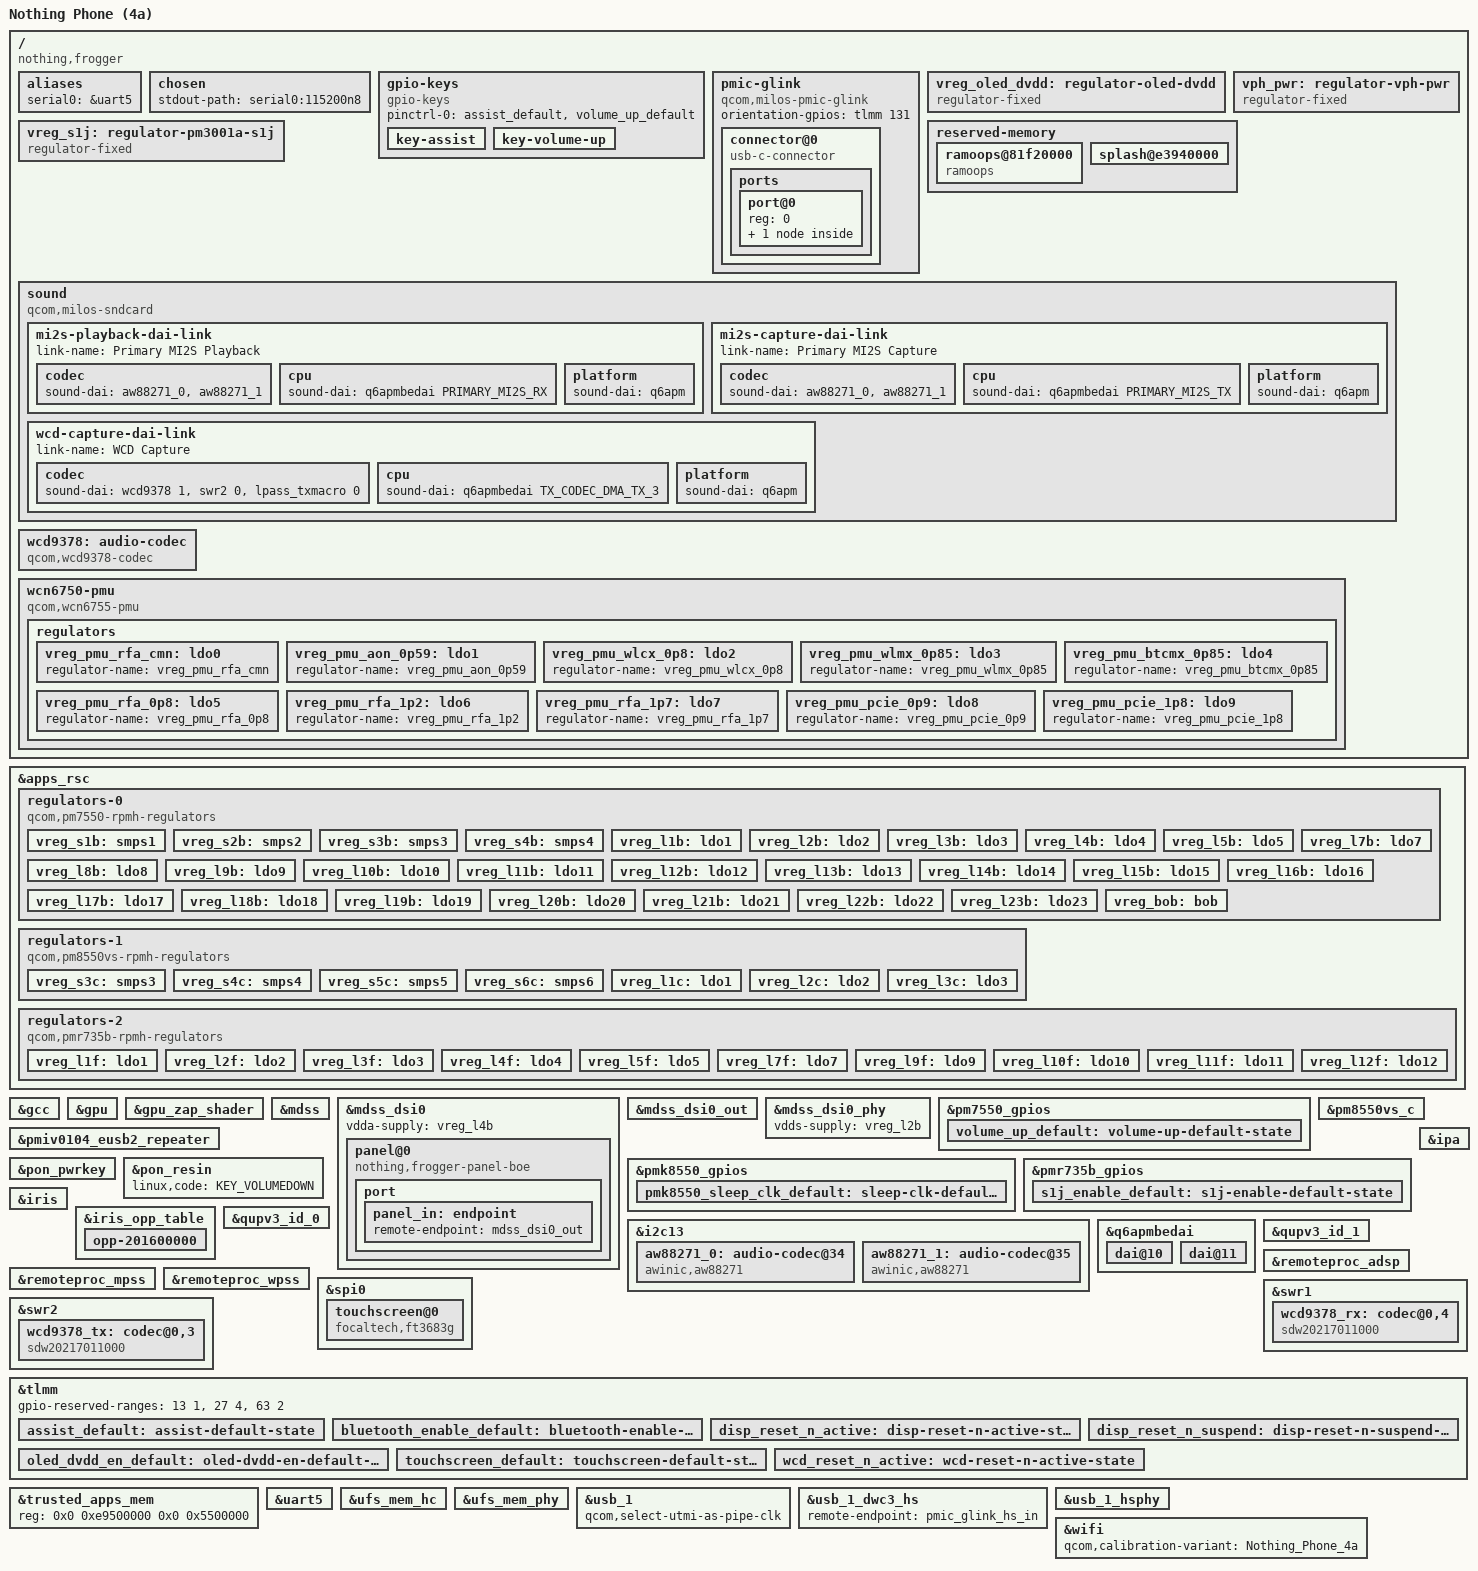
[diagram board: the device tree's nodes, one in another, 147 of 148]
// SPDX-License-Identifier: BSD-3-Clause

/dts-v1/;

#define PMIV0104_SID 7

#include <dt-bindings/pinctrl/qcom,pmic-gpio.h>
#include <dt-bindings/regulator/qcom,rpmh-regulator.h>

#include "milos.dtsi"
#include "pm7550.dtsi"
#include "pm8550vs.dtsi"
#include "pmiv0104.dtsi" /* PMIV0102 */
#include "pmk8550.dtsi" /* PMK7635 */
#include "pmr735b.dtsi"

/ {
	model = "Nothing Phone (4a)";
	compatible = "nothing,frogger", "qcom,milos";
	chassis-type = "handset";

	aliases {
		serial0 = &uart5;
	};

	chosen {
		stdout-path = "serial0:115200n8";
	};

	gpio-keys {
		compatible = "gpio-keys";

		pinctrl-0 = <&assist_default>, <&volume_up_default>;
		pinctrl-names = "default";

		key-assist {
			gpios = <&tlmm 71 GPIO_ACTIVE_LOW>;
			label = "Assistant";
			linux,code = <KEY_LEFTMETA>;
		};

		key-volume-up {
			gpios = <&pm7550_gpios 6 GPIO_ACTIVE_LOW>;
			label = "Volume Up";
			linux,code = <KEY_VOLUMEUP>;
		};
	};

	pmic-glink {
		compatible = "qcom,milos-pmic-glink",
			     "qcom,sm8550-pmic-glink",
			     "qcom,pmic-glink";
		#address-cells = <1>;
		#size-cells = <0>;
		orientation-gpios = <&tlmm 131 GPIO_ACTIVE_HIGH>;

		connector@0 {
			compatible = "usb-c-connector";
			reg = <0>;

			power-role = "dual";
			data-role = "dual";

			ports {
				#address-cells = <1>;
				#size-cells = <0>;

				port@0 {
					reg = <0>;

					pmic_glink_hs_in: endpoint {
						remote-endpoint = <&usb_1_dwc3_hs>;
					};
				};
			};
		};
	};

	vreg_oled_dvdd: regulator-oled-dvdd {
		compatible = "regulator-fixed";
		regulator-name = "oled_dvdd";
		regulator-min-microvolt = <1800000>;
		regulator-max-microvolt = <1800000>;

		gpio = <&tlmm 109 GPIO_ACTIVE_HIGH>;
		enable-active-high;

		pinctrl-0 = <&oled_dvdd_en_default>;
		pinctrl-names = "default";

		/* Left on by the bootloader */
		regulator-boot-on;
	};

	vreg_s1j: regulator-pm3001a-s1j {
		compatible = "regulator-fixed";
		regulator-name = "pm3001a_s1j";
		regulator-min-microvolt = <2200000>;
		regulator-max-microvolt = <2200000>;
		startup-delay-us = <1000>;

		/*
		 * WCN6750 iPA supply. Only the wcn6750-pmu consumes it, and
		 * nothing powers that sequencer up without Bluetooth, so keep
		 * it on for Wi-Fi (downstream enables it with the WLAN).
		 */
		regulator-always-on;

		gpio = <&pmr735b_gpios 1 GPIO_ACTIVE_HIGH>;
		enable-active-high;

		vin-supply = <&vph_pwr>;

		pinctrl-0 = <&s1j_enable_default>;
		pinctrl-names = "default";
	};

	vph_pwr: regulator-vph-pwr {
		compatible = "regulator-fixed";
		regulator-name = "vph_pwr";
		regulator-min-microvolt = <3700000>;
		regulator-max-microvolt = <3700000>;

		regulator-always-on;
		regulator-boot-on;
	};

	reserved-memory {
		#address-cells = <2>;
		#size-cells = <2>;
		ranges;

		ramoops@81f20000 {
			compatible = "ramoops";
			reg = <0x0 0x81f20000 0x0 0x400000>;
			console-size = <0x200000>;
			mem-type = <2>;
			pmsg-size = <0x200000>;
		};

		/*
		 * Bootloader splash buffer. ABL leaves the display running only
		 * when this node is named exactly "splash_region"; under any
		 * other name it powers display and controller down before
		 * booting Linux. Handing over a live splash breaks the MDSS
		 * memory path on this phone, so let ABL turn it off.
		 */
		splash@e3940000 {
			reg = <0x0 0xe3940000 0x0 0x2b00000>;
			no-map;
		};
	};

	sound {
		compatible = "qcom,milos-sndcard", "qcom,sm8450-sndcard";
		model = "Nothing Phone (4a)";
		audio-routing = "AMIC1", "MIC BIAS1",
				"AMIC2", "MIC BIAS2",
				"AMIC3", "MIC BIAS3",
				"TX SWR_INPUT0", "ADC1_OUTPUT",
				"TX SWR_INPUT4", "ADC2_OUTPUT",
				"TX SWR_INPUT8", "ADC3_OUTPUT";

		pinctrl-0 = <&i2s0_active>;
		pinctrl-1 = <&i2s0_sleep>;
		pinctrl-names = "default",
				"sleep";

		mi2s-playback-dai-link {
			link-name = "Primary MI2S Playback";

			codec {
				sound-dai = <&aw88271_0>, <&aw88271_1>;
			};

			cpu {
				sound-dai = <&q6apmbedai PRIMARY_MI2S_RX>;
			};

			platform {
				sound-dai = <&q6apm>;
			};
		};

		/* The amplifiers' V/I feedback, for DSP speaker protection */
		mi2s-capture-dai-link {
			link-name = "Primary MI2S Capture";

			codec {
				sound-dai = <&aw88271_0>, <&aw88271_1>;
			};

			cpu {
				sound-dai = <&q6apmbedai PRIMARY_MI2S_TX>;
			};

			platform {
				sound-dai = <&q6apm>;
			};
		};

		/* Keep this after the MI2S links: the V/I holder uses PCMs 0 and 1 */
		wcd-capture-dai-link {
			link-name = "WCD Capture";

			codec {
				sound-dai = <&wcd9378 1>, <&swr2 0>, <&lpass_txmacro 0>;
			};

			cpu {
				sound-dai = <&q6apmbedai TX_CODEC_DMA_TX_3>;
			};

			platform {
				sound-dai = <&q6apm>;
			};
		};
	};

	wcd9378: audio-codec {
		compatible = "qcom,wcd9378-codec";

		pinctrl-0 = <&wcd_reset_n_active>;
		pinctrl-names = "default";

		reset-gpios = <&tlmm 162 GPIO_ACTIVE_LOW>;

		vdd-buck-supply = <&vreg_l8b>;
		vdd-rxtx-supply = <&vreg_l7b>;
		vdd-io-supply = <&vreg_l7b>;
		vdd-mic-bias-supply = <&vreg_bob>;

		qcom,micbias1-microvolt = <2750000>;
		qcom,micbias2-microvolt = <2700000>;
		qcom,micbias3-microvolt = <2750000>;

		qcom,rx-device = <&wcd9378_rx>;
		qcom,tx-device = <&wcd9378_tx>;

		#sound-dai-cells = <1>;
	};

	wcn6750-pmu {
		compatible = "qcom,wcn6755-pmu", "qcom,wcn6750-pmu";

		vddaon-supply = <&vreg_s3b>;
		vddasd-supply = <&vreg_l7b>;
		vddpmu-supply = <&vreg_s3b>;
		vddrfa0p8-supply = <&vreg_s3b>;
		vddrfa1p2-supply = <&vreg_s2b>;
		vddrfa1p7-supply = <&vreg_s1b>;
		vddrfa2p2-supply = <&vreg_s1j>;

		bt-enable-gpios = <&tlmm 53 GPIO_ACTIVE_HIGH>;

		clocks = <&rpmhcc RPMH_RF_CLK1>;

		pinctrl-0 = <&bluetooth_enable_default>, <&pmk8550_sleep_clk_default>;
		pinctrl-names = "default";

		regulators {
			vreg_pmu_rfa_cmn: ldo0 {
				regulator-name = "vreg_pmu_rfa_cmn";
			};

			vreg_pmu_aon_0p59: ldo1 {
				regulator-name = "vreg_pmu_aon_0p59";
			};

			vreg_pmu_wlcx_0p8: ldo2 {
				regulator-name = "vreg_pmu_wlcx_0p8";
			};

			vreg_pmu_wlmx_0p85: ldo3 {
				regulator-name = "vreg_pmu_wlmx_0p85";
			};

			vreg_pmu_btcmx_0p85: ldo4 {
				regulator-name = "vreg_pmu_btcmx_0p85";
			};

			vreg_pmu_rfa_0p8: ldo5 {
				regulator-name = "vreg_pmu_rfa_0p8";
			};

			vreg_pmu_rfa_1p2: ldo6 {
				regulator-name = "vreg_pmu_rfa_1p2";
			};

			vreg_pmu_rfa_1p7: ldo7 {
				regulator-name = "vreg_pmu_rfa_1p7";
			};

			vreg_pmu_pcie_0p9: ldo8 {
				regulator-name = "vreg_pmu_pcie_0p9";
			};

			vreg_pmu_pcie_1p8: ldo9 {
				regulator-name = "vreg_pmu_pcie_1p8";
			};
		};
	};
};

&apps_rsc {
	regulators-0 {
		compatible = "qcom,pm7550-rpmh-regulators";

		vdd-l1-supply = <&vreg_s1b>;
		vdd-l2-l3-supply = <&vreg_s3b>;
		vdd-l4-l5-supply = <&vreg_s2b>;
		vdd-l7-supply = <&vreg_s1b>;
		vdd-l8-supply = <&vreg_s1b>;
		vdd-l9-l10-supply = <&vreg_s1b>;
		vdd-l11-supply = <&vreg_s1b>;
		vdd-l12-l14-supply = <&vreg_bob>;
		vdd-l13-l16-supply = <&vreg_bob>;
		vdd-l15-l17-l18-l19-l20-l21-l22-l23-supply = <&vreg_bob>;
		vdd-s1-supply = <&vph_pwr>;
		vdd-s2-supply = <&vph_pwr>;
		vdd-s3-supply = <&vph_pwr>;
		vdd-s4-supply = <&vph_pwr>;
		vdd-s5-supply = <&vph_pwr>;
		vdd-s6-supply = <&vph_pwr>;
		vdd-bob-supply = <&vph_pwr>;

		qcom,pmic-id = "b";

		vreg_s1b: smps1 {
			regulator-name = "vreg_s1b";
			regulator-min-microvolt = <1800000>;
			regulator-max-microvolt = <2080000>;
			regulator-initial-mode = <RPMH_REGULATOR_MODE_HPM>;
		};

		vreg_s2b: smps2 {
			regulator-name = "vreg_s2b";
			regulator-min-microvolt = <1256000>;
			regulator-max-microvolt = <1408000>;
			regulator-initial-mode = <RPMH_REGULATOR_MODE_HPM>;
		};

		vreg_s3b: smps3 {
			regulator-name = "vreg_s3b";
			regulator-min-microvolt = <880000>;
			regulator-max-microvolt = <1040000>;
			regulator-initial-mode = <RPMH_REGULATOR_MODE_HPM>;
		};

		vreg_s4b: smps4 {
			regulator-name = "vreg_s4b";
			regulator-min-microvolt = <300000>;
			regulator-max-microvolt = <1004000>;
			regulator-initial-mode = <RPMH_REGULATOR_MODE_HPM>;
		};

		vreg_l1b: ldo1 {
			regulator-name = "vreg_l1b";
			regulator-min-microvolt = <1800000>;
			regulator-max-microvolt = <1800000>;
			regulator-initial-mode = <RPMH_REGULATOR_MODE_HPM>;
		};

		vreg_l2b: ldo2 {
			regulator-name = "vreg_l2b";
			regulator-min-microvolt = <880000>;
			regulator-max-microvolt = <912000>;
			regulator-initial-mode = <RPMH_REGULATOR_MODE_HPM>;
		};

		vreg_l3b: ldo3 {
			regulator-name = "vreg_l3b";
			regulator-min-microvolt = <880000>;
			regulator-max-microvolt = <912000>;
			regulator-initial-mode = <RPMH_REGULATOR_MODE_HPM>;
		};

		vreg_l4b: ldo4 {
			regulator-name = "vreg_l4b";
			regulator-min-microvolt = <1200000>;
			regulator-max-microvolt = <1200000>;
			regulator-initial-mode = <RPMH_REGULATOR_MODE_HPM>;
		};

		vreg_l5b: ldo5 {
			regulator-name = "vreg_l5b";
			regulator-min-microvolt = <1200000>;
			regulator-max-microvolt = <1200000>;
			regulator-initial-mode = <RPMH_REGULATOR_MODE_HPM>;
		};

		vreg_l7b: ldo7 {
			regulator-name = "vreg_l7b";
			regulator-min-microvolt = <1800000>;
			regulator-max-microvolt = <1800000>;
			regulator-initial-mode = <RPMH_REGULATOR_MODE_HPM>;
		};

		vreg_l8b: ldo8 {
			regulator-name = "vreg_l8b";
			regulator-min-microvolt = <1800000>;
			regulator-max-microvolt = <1800000>;
			regulator-initial-mode = <RPMH_REGULATOR_MODE_HPM>;
		};

		vreg_l9b: ldo9 {
			regulator-name = "vreg_l9b";
			regulator-min-microvolt = <1800000>;
			regulator-max-microvolt = <1800000>;
			regulator-initial-mode = <RPMH_REGULATOR_MODE_HPM>;
		};

		vreg_l10b: ldo10 {
			regulator-name = "vreg_l10b";
			regulator-min-microvolt = <1800000>;
			regulator-max-microvolt = <1800000>;
			regulator-initial-mode = <RPMH_REGULATOR_MODE_HPM>;
		};

		vreg_l11b: ldo11 {
			regulator-name = "vreg_l11b";
			regulator-min-microvolt = <1800000>;
			regulator-max-microvolt = <1800000>;
			regulator-initial-mode = <RPMH_REGULATOR_MODE_HPM>;
		};

		vreg_l12b: ldo12 {
			regulator-name = "vreg_l12b";
			/*
			 * Skip voltage voting for UFS VCC.
			 */
			regulator-initial-mode = <RPMH_REGULATOR_MODE_HPM>;
		};

		vreg_l13b: ldo13 {
			regulator-name = "vreg_l13b";
			regulator-min-microvolt = <2700000>;
			regulator-max-microvolt = <3300000>;
			regulator-initial-mode = <RPMH_REGULATOR_MODE_HPM>;
		};

		vreg_l14b: ldo14 {
			regulator-name = "vreg_l14b";
			regulator-min-microvolt = <3300000>;
			regulator-max-microvolt = <3304000>;
			regulator-initial-mode = <RPMH_REGULATOR_MODE_HPM>;
		};

		vreg_l15b: ldo15 {
			regulator-name = "vreg_l15b";
			regulator-min-microvolt = <3300000>;
			regulator-max-microvolt = <3304000>;
			regulator-initial-mode = <RPMH_REGULATOR_MODE_HPM>;
		};

		vreg_l16b: ldo16 {
			regulator-name = "vreg_l16b";
			regulator-min-microvolt = <3304000>;
			regulator-max-microvolt = <3304000>;
			regulator-initial-mode = <RPMH_REGULATOR_MODE_HPM>;
		};

		vreg_l17b: ldo17 {
			regulator-name = "vreg_l17b";
			regulator-min-microvolt = <3104000>;
			regulator-max-microvolt = <3104000>;
			regulator-initial-mode = <RPMH_REGULATOR_MODE_HPM>;
		};

		vreg_l18b: ldo18 {
			regulator-name = "vreg_l18b";
			regulator-min-microvolt = <2800000>;
			regulator-max-microvolt = <2800000>;
			regulator-initial-mode = <RPMH_REGULATOR_MODE_HPM>;
		};

		vreg_l19b: ldo19 {
			regulator-name = "vreg_l19b";
			regulator-min-microvolt = <3000000>;
			regulator-max-microvolt = <3000000>;
			regulator-initial-mode = <RPMH_REGULATOR_MODE_HPM>;
		};

		vreg_l20b: ldo20 {
			regulator-name = "vreg_l20b";
			regulator-min-microvolt = <1620000>;
			regulator-max-microvolt = <3544000>;
			regulator-initial-mode = <RPMH_REGULATOR_MODE_HPM>;
		};

		vreg_l21b: ldo21 {
			regulator-name = "vreg_l21b";
			regulator-min-microvolt = <1620000>;
			regulator-max-microvolt = <3544000>;
			regulator-initial-mode = <RPMH_REGULATOR_MODE_HPM>;
		};

		vreg_l22b: ldo22 {
			regulator-name = "vreg_l22b";
			regulator-min-microvolt = <3296000>;
			regulator-max-microvolt = <3296000>;
			regulator-initial-mode = <RPMH_REGULATOR_MODE_HPM>;
		};

		vreg_l23b: ldo23 {
			regulator-name = "vreg_l23b";
			regulator-min-microvolt = <1650000>;
			regulator-max-microvolt = <3544000>;
			regulator-initial-mode = <RPMH_REGULATOR_MODE_HPM>;
		};

		vreg_bob: bob {
			regulator-name = "vreg_bob";
			regulator-min-microvolt = <3008000>;
			regulator-max-microvolt = <3960000>;
			regulator-initial-mode = <RPMH_REGULATOR_MODE_HPM>;
		};
	};

	regulators-1 {
		compatible = "qcom,pm8550vs-rpmh-regulators";

		vdd-l1-supply = <&vreg_s3b>;
		vdd-l2-supply = <&vreg_s3b>;
		vdd-l3-supply = <&vreg_s3b>;
		vdd-s3-supply = <&vph_pwr>;
		vdd-s4-supply = <&vph_pwr>;
		vdd-s5-supply = <&vph_pwr>;
		vdd-s6-supply = <&vph_pwr>;

		qcom,pmic-id = "c";

		vreg_s3c: smps3 {
			regulator-name = "vreg_s3c";
			regulator-min-microvolt = <1010000>;
			regulator-max-microvolt = <1120000>;
			regulator-initial-mode = <RPMH_REGULATOR_MODE_HPM>;
		};

		vreg_s4c: smps4 {
			regulator-name = "vreg_s4c";
			regulator-min-microvolt = <352000>;
			regulator-max-microvolt = <812000>;
			regulator-initial-mode = <RPMH_REGULATOR_MODE_HPM>;
		};

		vreg_s5c: smps5 {
			regulator-name = "vreg_s5c";
			regulator-min-microvolt = <540000>;
			regulator-max-microvolt = <884000>;
			regulator-initial-mode = <RPMH_REGULATOR_MODE_HPM>;
		};

		vreg_s6c: smps6 {
			regulator-name = "vreg_s6c";
			regulator-min-microvolt = <352000>;
			regulator-max-microvolt = <904000>;
			regulator-initial-mode = <RPMH_REGULATOR_MODE_HPM>;
		};

		vreg_l1c: ldo1 {
			regulator-name = "vreg_l1c";
			regulator-min-microvolt = <320000>;
			regulator-max-microvolt = <1004000>;
			regulator-initial-mode = <RPMH_REGULATOR_MODE_HPM>;
		};

		vreg_l2c: ldo2 {
			regulator-name = "vreg_l2c";
			regulator-min-microvolt = <320000>;
			regulator-max-microvolt = <650000>;
			regulator-initial-mode = <RPMH_REGULATOR_MODE_HPM>;
		};

		vreg_l3c: ldo3 {
			regulator-name = "vreg_l3c";
			regulator-min-microvolt = <320000>;
			regulator-max-microvolt = <912000>;
			regulator-initial-mode = <RPMH_REGULATOR_MODE_HPM>;
		};
	};

	regulators-2 {
		compatible = "qcom,pmr735b-rpmh-regulators";

		vdd-l1-l2-supply = <&vreg_s3b>;
		vdd-l3-supply = <&vreg_s3b>;
		vdd-l4-supply = <&vreg_s1b>;
		vdd-l5-supply = <&vreg_s2b>;
		vdd-l7-l8-supply = <&vreg_s2b>;
		vdd-l9-supply = <&vreg_s3b>;
		vdd-l10-supply = <&vreg_s1b>;
		vdd-l11-supply = <&vreg_s3b>;
		vdd-l12-supply = <&vreg_s3b>;

		qcom,pmic-id = "f";

		vreg_l1f: ldo1 {
			regulator-name = "vreg_l1f";
			regulator-min-microvolt = <852000>;
			regulator-max-microvolt = <950000>;
			regulator-initial-mode = <RPMH_REGULATOR_MODE_HPM>;
		};

		vreg_l2f: ldo2 {
			regulator-name = "vreg_l2f";
			regulator-min-microvolt = <751000>;
			regulator-max-microvolt = <824000>;
			regulator-initial-mode = <RPMH_REGULATOR_MODE_HPM>;
		};

		vreg_l3f: ldo3 {
			regulator-name = "vreg_l3f";
			regulator-min-microvolt = <650000>;
			regulator-max-microvolt = <880000>;
			regulator-initial-mode = <RPMH_REGULATOR_MODE_HPM>;
		};

		vreg_l4f: ldo4 {
			regulator-name = "vreg_l4f";
			regulator-min-microvolt = <1700000>;
			regulator-max-microvolt = <1950000>;
			regulator-initial-mode = <RPMH_REGULATOR_MODE_HPM>;
		};

		vreg_l5f: ldo5 {
			regulator-name = "vreg_l5f";
			regulator-min-microvolt = <1140000>;
			regulator-max-microvolt = <1260000>;
			regulator-initial-mode = <RPMH_REGULATOR_MODE_HPM>;
		};

		vreg_l7f: ldo7 {
			regulator-name = "vreg_l7f";
			regulator-min-microvolt = <1080000>;
			regulator-max-microvolt = <1350000>;
			regulator-initial-mode = <RPMH_REGULATOR_MODE_HPM>;
		};

		vreg_l9f: ldo9 {
			regulator-name = "vreg_l9f";
			regulator-min-microvolt = <870000>;
			regulator-max-microvolt = <970000>;
			regulator-initial-mode = <RPMH_REGULATOR_MODE_HPM>;
		};

		vreg_l10f: ldo10 {
			regulator-name = "vreg_l10f";
			regulator-min-microvolt = <1500000>;
			regulator-max-microvolt = <1800000>;
			regulator-initial-mode = <RPMH_REGULATOR_MODE_HPM>;
		};

		vreg_l11f: ldo11 {
			regulator-name = "vreg_l11f";
			regulator-min-microvolt = <320000>;
			regulator-max-microvolt = <864000>;
			regulator-initial-mode = <RPMH_REGULATOR_MODE_HPM>;
		};

		vreg_l12f: ldo12 {
			regulator-name = "vreg_l12f";
			regulator-min-microvolt = <480000>;
			regulator-max-microvolt = <884000>;
			regulator-initial-mode = <RPMH_REGULATOR_MODE_HPM>;
		};
	};
};

&gcc {
	protected-clocks = <GCC_PCIE_1_AUX_CLK>, <GCC_PCIE_1_AUX_CLK_SRC>,
			   <GCC_PCIE_1_CFG_AHB_CLK>, <GCC_PCIE_1_MSTR_AXI_CLK>,
			   <GCC_PCIE_1_PHY_RCHNG_CLK>, <GCC_PCIE_1_PHY_RCHNG_CLK_SRC>,
			   <GCC_PCIE_1_PIPE_CLK>, <GCC_PCIE_1_PIPE_CLK_SRC>,
			   <GCC_PCIE_1_PIPE_DIV2_CLK>, <GCC_PCIE_1_PIPE_DIV2_CLK_SRC>,
			   <GCC_PCIE_1_SLV_AXI_CLK>, <GCC_PCIE_1_SLV_Q2A_AXI_CLK>;
};

&gpu {
	status = "okay";
};

&gpu_zap_shader {
	firmware-name = "qcom/milos/nothing/frogger/gen80300_zap.mbn";
};

&mdss {
	status = "okay";
};

&mdss_dsi0 {
	vdda-supply = <&vreg_l4b>;

	status = "okay";

	panel@0 {
		compatible = "nothing,frogger-panel-boe";
		reg = <0>;

		reset-gpios = <&tlmm 12 GPIO_ACTIVE_LOW>;

		vddio-supply = <&vreg_l9b>;
		dvdd-supply = <&vreg_oled_dvdd>;
		vci-supply = <&vreg_l19b>;

		pinctrl-0 = <&disp_reset_n_active>;
		pinctrl-1 = <&disp_reset_n_suspend>;
		pinctrl-names = "default",
				"sleep";

		port {
			panel_in: endpoint {
				remote-endpoint = <&mdss_dsi0_out>;
			};
		};
	};
};

&mdss_dsi0_out {
	data-lanes = <0 1 2 3>;
	remote-endpoint = <&panel_in>;
};

&mdss_dsi0_phy {
	vdds-supply = <&vreg_l2b>;

	status = "okay";
};

&pm7550_gpios {
	volume_up_default: volume-up-default-state {
		pins = "gpio6";
		function = PMIC_GPIO_FUNC_NORMAL;
		power-source = <1>;
		bias-pull-up;
	};
};

&pm8550vs_c {
	status = "okay";
};

&pmiv0104_eusb2_repeater {
	vdd18-supply = <&vreg_l7b>;
	vdd3-supply = <&vreg_l17b>;

	qcom,tune-res-fsdif = /bits/ 8 <0x5>;
	qcom,tune-usb2-amplitude = /bits/ 8 <0x8>;
	qcom,tune-usb2-disc-thres = /bits/ 8 <0x7>;
	qcom,tune-usb2-preem = /bits/ 8 <0x6>;
};

&pmk8550_gpios {
	pmk8550_sleep_clk_default: sleep-clk-default-state {
		pins = "gpio5";
		function = "func1";
		input-disable;
		output-enable;
		bias-disable;
		power-source = <0>;
	};
};

&pmr735b_gpios {
	s1j_enable_default: s1j-enable-default-state {
		pins = "gpio1";
		function = PMIC_GPIO_FUNC_NORMAL;
		power-source = <0>;
		bias-disable;
		output-low;
	};
};

&pon_pwrkey {
	status = "okay";
};

&pon_resin {
	linux,code = <KEY_VOLUMEDOWN>;

	status = "okay";
};

&i2c13 {
	status = "okay";

	/* Speaker amplifiers: 0x34 drives the top earpiece capsule, 0x35 the bottom speaker */
	aw88271_0: audio-codec@34 {
		compatible = "awinic,aw88271";
		reg = <0x34>;

		reset-gpios = <&tlmm 141 GPIO_ACTIVE_LOW>;
		firmware-name = "qcom/milos/nothing/frogger/aw882xx_acf.bin";
		sound-name-prefix = "Amp 0x34";

		awinic,audio-channel = <0>;
		awinic,transducer = "earpiece";

		#sound-dai-cells = <0>;
	};

	aw88271_1: audio-codec@35 {
		compatible = "awinic,aw88271";
		reg = <0x35>;

		reset-gpios = <&tlmm 142 GPIO_ACTIVE_LOW>;
		firmware-name = "qcom/milos/nothing/frogger/aw882xx_acf.bin";
		sound-name-prefix = "Amp 0x35";

		awinic,audio-channel = <1>;
		awinic,transducer = "speaker";

		#sound-dai-cells = <0>;
	};
};

&ipa {
	firmware-name = "qcom/milos/nothing/frogger/ipa_fws.mbn";
	memory-region = <&ipa_fw_mem>;

	qcom,gsi-loader = "self";

	status = "okay";
};

&iris {
	firmware-name = "qcom/milos/nothing/frogger/vpu20_2v.mbn";

	status = "okay";
};

&iris_opp_table {
	/*
	 * This phone's video SKU efuse (0x221c8118 bit 10) reads 1: stock
	 * msm_video then uses volcano SKU1, whose only frequency is 201.6 MHz.
	 */
	/delete-node/ opp-240000000;
	/delete-node/ opp-338000000;
	/delete-node/ opp-366000000;
	/delete-node/ opp-444000000;
	/delete-node/ opp-552000000;

	opp-201600000 {
		opp-hz = /bits/ 64 <201600000>;
		required-opps = <&rpmhpd_opp_low_svs>,
				<&rpmhpd_opp_svs>;
	};
};

&q6apmbedai {
	#address-cells = <1>;
	#size-cells = <0>;

	dai@10 {
		reg = <PRIMARY_MI2S_RX>;
		clocks = <&q6prmcc LPASS_CLK_ID_PRI_MI2S_IBIT LPASS_CLK_ATTRIBUTE_COUPLE_NO>;
		clock-names = "bclk";
	};

	dai@11 {
		reg = <PRIMARY_MI2S_TX>;
		clocks = <&q6prmcc LPASS_CLK_ID_PRI_MI2S_IBIT LPASS_CLK_ATTRIBUTE_COUPLE_NO>;
		clock-names = "bclk";
	};
};

&qupv3_id_0 {
	status = "okay";
};

&qupv3_id_1 {
	status = "okay";
};

&remoteproc_adsp {
	firmware-name = "qcom/milos/nothing/frogger/adsp.mbn",
			"qcom/milos/nothing/frogger/adsp_dtb.mbn";

	status = "okay";
};

&remoteproc_mpss {
	firmware-name = "qcom/milos/nothing/frogger/modem.mbn";

	status = "okay";
};

&remoteproc_wpss {
	firmware-name = "qcom/milos/nothing/frogger/wpss.mbn";

	status = "okay";
};

&spi0 {
	status = "okay";

	touchscreen@0 {
		compatible = "focaltech,ft3683g";
		reg = <0>;
		spi-max-frequency = <12000000>;

		interrupts-extended = <&tlmm 19 IRQ_TYPE_EDGE_FALLING>;
		reset-gpios = <&tlmm 20 GPIO_ACTIVE_LOW>;

		vci-supply = <&vreg_l22b>;
		vddio-supply = <&vreg_l11b>;

		pinctrl-0 = <&touchscreen_default>;
		pinctrl-names = "default";

		touchscreen-size-x = <1224>;
		touchscreen-size-y = <2720>;
	};
};

&swr1 {
	status = "okay";

	/* WCD9378 RX */
	wcd9378_rx: codec@0,4 {
		compatible = "sdw20217011000";
		reg = <0 4>;
		qcom,port-mapping = <1 2 3 4 5>;
	};
};

&swr2 {
	status = "okay";

	/* WCD9378 TX */
	wcd9378_tx: codec@0,3 {
		compatible = "sdw20217011000";
		reg = <0 3>;

		/*
		 * WCD9378 TX port 1 (ADC1)          <=> SWR2 port 1 (SWRM_TX1)
		 * WCD9378 TX port 2 (ADC2)          <=> SWR2 port 2 (SWRM_TX2)
		 * WCD9378 TX port 3 (ADC3)          <=> SWR2 port 3 (SWRM_TX3)
		 * (one master port per ADC, as stock's ADCn ChMap = SWRM_TXn_CH1)
		 * WCD9378 TX port 4 (DMIC0,1, MBHC) <=> SWR2 port 2
		 * WCD9378 TX port 5 (DMIC2..5)      <=> SWR2 port 3
		 */
		qcom,control-device;
		qcom,port-mapping = <1 2 3 2 3>;
	};
};

&tlmm {
	gpio-reserved-ranges = <13 1>, /* Display */
			       <27 4>, /* Secure, reserved by downstream */
			       <63 2>; /* WLAN UART */

	assist_default: assist-default-state {
		pins = "gpio71";
		function = "gpio";
		bias-pull-up;
	};

	bluetooth_enable_default: bluetooth-enable-default-state {
		pins = "gpio53";
		function = "gpio";
		output-low;
		bias-disable;
	};

	disp_reset_n_active: disp-reset-n-active-state {
		pins = "gpio12";
		function = "gpio";
		drive-strength = <8>;
		bias-disable;
	};

	disp_reset_n_suspend: disp-reset-n-suspend-state {
		pins = "gpio12";
		function = "gpio";
		drive-strength = <2>;
		bias-pull-down;
	};

	oled_dvdd_en_default: oled-dvdd-en-default-state {
		pins = "gpio109";
		function = "gpio";
		drive-strength = <2>;
		bias-disable;
	};

	touchscreen_default: touchscreen-default-state {
		pins = "gpio19", "gpio20";
		function = "gpio";
		drive-strength = <8>;
		bias-pull-up;
	};

	wcd_reset_n_active: wcd-reset-n-active-state {
		pins = "gpio162";
		function = "gpio";
		drive-strength = <16>;
		output-high;
	};
};

&trusted_apps_mem {
	reg = <0x0 0xe9500000 0x0 0x5500000>;
};

/*
 * UART_RX and UART_TX are routed to test points on board, not
 * available over USB.
 */
&uart5 {
	status = "okay";
};

&ufs_mem_hc {
	reset-gpios = <&tlmm 167 GPIO_ACTIVE_LOW>;

	vcc-supply = <&vreg_l12b>;
	vcc-max-microamp = <800000>;
	vccq-supply = <&vreg_l5f>;
	vccq-max-microamp = <750000>;

	status = "okay";
};

&ufs_mem_phy {
	vdda-phy-supply = <&vreg_l2b>;
	vdda-pll-supply = <&vreg_l4b>;

	status = "okay";
};

&usb_1 {
	/* USB 2.0 only, HW does not support USB 3.x */
	qcom,select-utmi-as-pipe-clk;

	status = "okay";
};

&usb_1_dwc3_hs {
	remote-endpoint = <&pmic_glink_hs_in>;
};

&usb_1_hsphy {
	vdd-supply = <&vreg_l2b>;
	vdda12-supply = <&vreg_l4b>;

	phys = <&pmiv0104_eusb2_repeater>;

	status = "okay";
};

&wifi {
	qcom,calibration-variant = "Nothing_Phone_4a";

	status = "okay";
};
